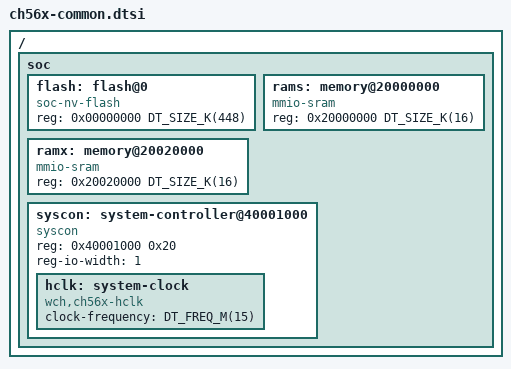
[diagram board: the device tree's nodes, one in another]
/*
 * Copyright (c) 2023 Chen Xingyu <hi@xingrz.me>
 * SPDX-License-Identifier: Apache-2.0
 */

#include <mem.h>
#include <freq.h>

#include <wch/qingke-v3.dtsi>

/ {
	soc {
		flash: flash@0 {
			compatible = "soc-nv-flash";
			reg = <0x00000000 DT_SIZE_K(448)>;
		};

		rams: memory@20000000 {
			compatible = "mmio-sram";
			reg = <0x20000000 DT_SIZE_K(16)>;
		};

		ramx: memory@20020000 {
			compatible = "mmio-sram";
			reg = <0x20020000 DT_SIZE_K(16)>;
		};

		syscon: system-controller@40001000 {
			compatible = "syscon";
			reg = <0x40001000 0x20>;
			reg-io-width = <1>;

			hclk: system-clock {
				compatible = "wch,ch56x-hclk";
				clock-frequency = <DT_FREQ_M(15)>;
				#clock-cells = <2>;
			};
		};
	};
};
